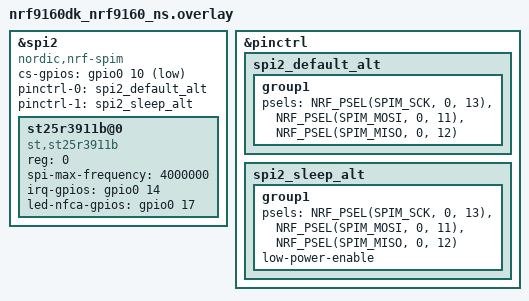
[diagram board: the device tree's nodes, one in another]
&spi2 {
	compatible = "nordic,nrf-spim";
	status = "okay";
	cs-gpios = <&gpio0 10 GPIO_ACTIVE_LOW>;

	pinctrl-0 = <&spi2_default_alt>;
	pinctrl-1 = <&spi2_sleep_alt>;
	pinctrl-names = "default", "sleep";
	st25r3911b@0 {
		compatible = "st,st25r3911b";
		reg = <0>;
		spi-max-frequency = <4000000>;
		irq-gpios = <&gpio0 14 GPIO_ACTIVE_HIGH>;
		led-nfca-gpios = <&gpio0 17 GPIO_ACTIVE_HIGH>;
	};
};

&pinctrl {
	spi2_default_alt: spi2_default_alt {
		group1 {
			psels = <NRF_PSEL(SPIM_SCK, 0, 13)>,
			        <NRF_PSEL(SPIM_MOSI, 0, 11)>,
			        <NRF_PSEL(SPIM_MISO, 0, 12)>;
		};
	};

	spi2_sleep_alt: spi2_sleep_alt {
		group1 {
			psels = <NRF_PSEL(SPIM_SCK, 0, 13)>,
			        <NRF_PSEL(SPIM_MOSI, 0, 11)>,
			        <NRF_PSEL(SPIM_MISO, 0, 12)>;
			low-power-enable;
		};
	};

};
